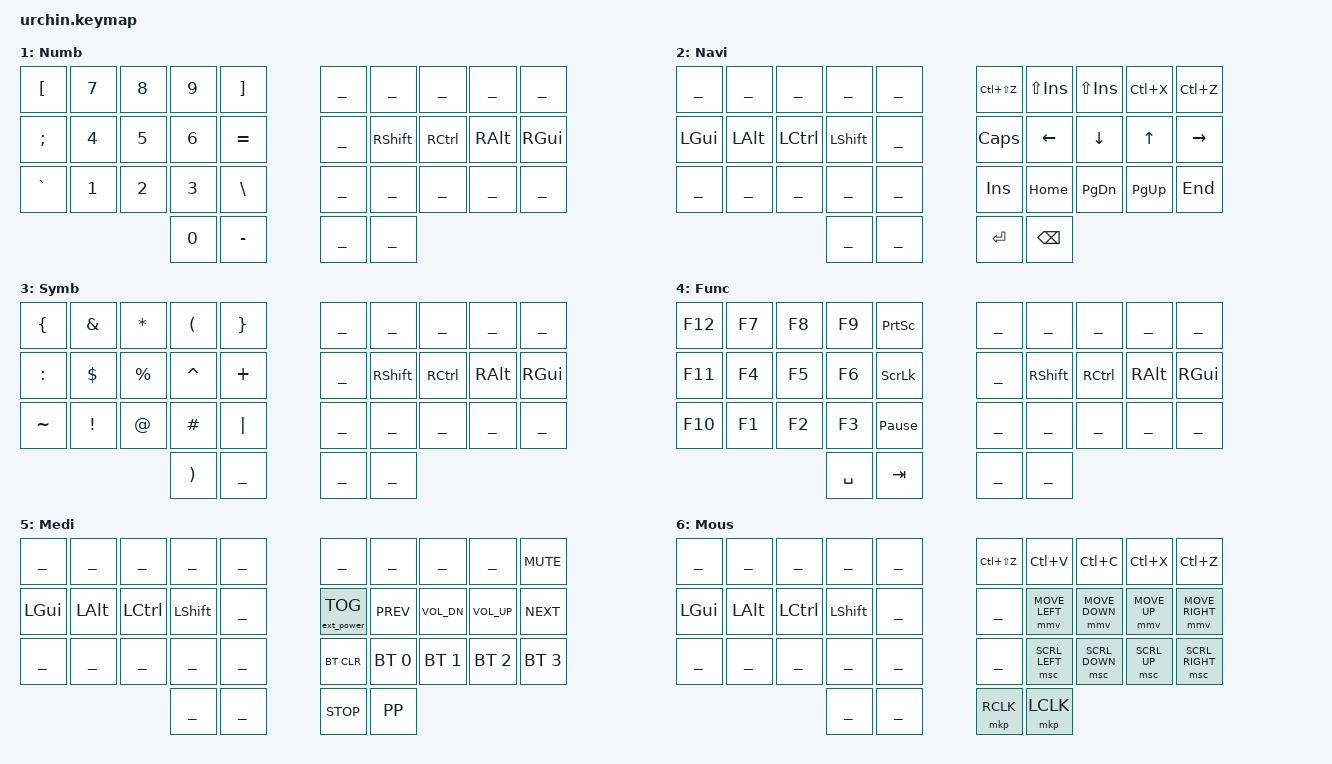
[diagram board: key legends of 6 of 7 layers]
// Copyright (c) 2022 The ZMK Contributors
// SPDX-License-Identifier: MIT

#include <behaviors.dtsi>
#include <dt-bindings/zmk/keys.h>
#include <dt-bindings/zmk/bt.h>
#include <dt-bindings/zmk/outputs.h>
#include <dt-bindings/zmk/ext_power.h>
#include <dt-bindings/zmk/pointing.h>

#include "zmk-helpers/helper.h"
#include "zmk-helpers/key-labels/34.h"

#include "constants.h"

#include "behaviors/combos.dtsi"
#include "behaviors/mod-morph.dtsi"
#include "behaviors/hold-tap.dtsi"

/ {
    keymap {
        compatible = "zmk,keymap";

        base {
            display-name = "Base";
            bindings = <
        //╭──────────┬──────────┬──────────┬──────────┬──────────╮   ╭──────────┬──────────┬──────────┬──────────┬──────────╮
        //│  Q       │  W       │  F       │  P       │  B       │   │  J       │  L       │  U       │  Y       │  ' "     │
            &kp Q      &kp W      &kp F      &kp P      &kp B          &kp J      &kp L      &kp U      &kp Y      &kp SQT
        //├──────────┼──────────┼──────────┼──────────┼──────────┤   ├──────────┼──────────┼──────────┼──────────┼──────────┤
        //│  A       │  R       │  S       │  T       │  G       │   │  M       │  N       │  E       │  I       │  O       │
            HRML(A,        R,         S,         T)     &kp G          &kp M      HRMR(N,        E,         I,        O)
        //├──────────┼──────────┼──────────┼──────────┼──────────┤   ├──────────┼──────────┼──────────┼──────────┼──────────┤
        //│  Z       │  X       │  C       │  D       │  V       │   │  K       │  H       │ , <      │ . >      │ / ?      │
            &kp Z      &kp X      &kp C      &kp D      &kp V          &kp K      &kp H      &kp COMMA  &kp DOT    &kp FSLH
        //╰──────────┴──────────┴──────────┼──────────┼──────────┤   ├──────────┼──────────┼──────────┴──────────┴──────────╯
                                            &lt NAV SPACE &lt MOU TAB  &lt SYM ENTER &bs_del_num
        //                                 ╰──────────┴──────────╯   ╰──────────┴──────────╯
            >;
        };

        // 1. NUM - number
        number {
            display-name = "Numb";
            bindings = <
        //╭──────────┬──────────┬──────────┬──────────┬──────────╮   ╭──────────┬──────────┬──────────┬──────────┬──────────╮
        //│  [       │  7       │  8       │  9       │  ]       │   │          │          │          │          │          │
            &kp LBKT   &kp N7     &kp N8     &kp N9     &kp RBKT       ___        ___        ___        ___        ___ 
        //├──────────┼──────────┼──────────┼──────────┼──────────┤   ├──────────┼──────────┼──────────┼──────────┼──────────┤
        //│  ;       │  4       │  5       │  6       │  =       │   │          │  SHIFT   │  CTRL    │  ALT     │  GUI     │
            &kp SEMI   &kp N4     &kp N5     &kp N6     &kp EQUAL      ___        &kp RSHFT  &kp RCTRL  &kp RALT   &kp RGUI
        //├──────────┼──────────┼──────────┼──────────┼──────────┤   ├──────────┼──────────┼──────────┼──────────┼──────────┤
        //│ `        │  1       │  2       │  3       │  \       │   │          │          │          │          │          │
            &kp GRAVE  &kp N1     &kp N2     &kp N3     &kp BSLH       ___        ___        ___        ___        ___ 
        //╰──────────┴──────────┴──────────┼──────────┼──────────┤   ├──────────┼──────────┼──────────┴──────────┴──────────╯
                                             &kp N0     &kp MINUS      ___        ___
        //                                 ╰──────────┴──────────╯   ╰──────────┴──────────╯
            >;
        };

        // 2. NAV - navigation
        navigation {
            display-name = "Navi";
            bindings = <
        //╭──────────┬──────────┬──────────┬──────────┬──────────╮   ╭──────────┬──────────┬──────────┬──────────┬──────────╮
        //│          │          │          │          │          │   │  REDO    │  PASTE   │  COPY    │  CUT     │  UNDO    │
            ___        ___        ___        ___        ___            &kp LC(LS(Z)) &kp LS(INS) &kp LS(INS) &kp LC(X) &kp LC(Z) 
        //├──────────┼──────────┼──────────┼──────────┼──────────┤   ├──────────┼──────────┼──────────┼──────────┼──────────┤
        //│  GUI     │  ALT     │  CTRL    │  SHIFT   │          │   │ CAPSLOCK │  LEFT A  │  DOWN A  │  UP A    │  RIGHT A │
            &kp LGUI   &kp LALT   &kp LCTRL  &kp LSHFT  ___            &kp CAPS   &kp LEFT   &kp DOWN   &kp UP     &kp RIGHT 
        //├──────────┼──────────┼──────────┼──────────┼──────────┤   ├──────────┼──────────┼──────────┼──────────┼──────────┤
        //│          │          │          │          │          │   │  INSERT  │  HOME    │  PAGE D  │  PAGE U  │  END     │
            ___        ___        ___        ___        ___            &kp INS    &kp HOME   &kp PG_DN  &kp PG_UP  &kp END
        //╰──────────┴──────────┴──────────┼──────────┼──────────┤   ├──────────┼──────────┼──────────┴──────────┴──────────╯
                                             ___        ___            &kp ENTER  &kp BSPC
        //                                 ╰──────────┴──────────╯   ╰──────────┴──────────╯
            >;
        };

        // 3. SYM - symbol
        symbol {
            display-name = "Symb";
            bindings = <
        //╭──────────┬──────────┬──────────┬──────────┬──────────╮   ╭──────────┬──────────┬──────────┬──────────┬──────────╮
        //│  {       │  &       │  *       │  (       │  }       │   │          │          │          │          │          │
            &kp LBRC   &kp AMPS   &kp ASTRK  &kp LPAR   &kp RBRC       ___        ___        ___        ___        ___
        //├──────────┼──────────┼──────────┼──────────┼──────────┤   ├──────────┼──────────┼──────────┼──────────┼──────────┤
        //│  :       │  $       │  %       │  ^       │  +       │   │          │  SHIFT   │  CTRL    │  ALT     │  GUI     │
            &kp COLON  &kp DLLR   &kp PRCNT  &kp CARET  &kp PLUS       ___        &kp RSHFT  &kp RCTRL  &kp RALT   &kp RGUI
        //├──────────┼──────────┼──────────┼──────────┼──────────┤   ├──────────┼──────────┼──────────┼──────────┼──────────┤
        //│  ~       │  !       │  @       │  #       │  |       │   │          │          │          │          │          │
            &kp TILDE  &kp EXCL   &kp AT     &kp HASH   &kp PIPE       ___        ___        ___        ___        ___
        //╰──────────┴──────────┴──────────┼──────────┼──────────┤   ├──────────┼──────────┼──────────┴──────────┴──────────╯
                                             &kp RPAR   &kp UNDER      ___        ___
        //                                 ╰──────────┴──────────╯   ╰──────────┴──────────╯
            >;
        };

        // 4. FUN - function
        function {
            display-name = "Func";
            bindings = <
        //╭──────────┬──────────┬──────────┬──────────┬──────────╮   ╭──────────┬──────────┬──────────┬──────────┬──────────╮
        //│  F12     │  F7      │  F8      │  F9      │ PRINTSCR │   │          │          │          │          │          │
            &kp F12    &kp F7     &kp F8     &kp F9     &kp PSCRN      ___        ___        ___        ___        ___ 
        //├──────────┼──────────┼──────────┼──────────┼──────────┤   ├──────────┼──────────┼──────────┼──────────┼──────────┤
        //│  F11     │  F4      │  F5      │  F6      │ SCROLLLO │   │          │  SHIFT   │  CTRL    │  ALT     │  GUI     │
            &kp F11    &kp F4     &kp F5     &kp F6     &kp SLCK       ___        &kp RSHFT  &kp RCTRL  &kp RALT   &kp RGUI
        //├──────────┼──────────┼──────────┼──────────┼──────────┤   ├──────────┼──────────┼──────────┼──────────┼──────────┤
        //│  F10     │  F1      │  F2      │  F3      │ PAUS/BRK │   │          │          │          │          │          │
            &kp F10    &kp F1     &kp F2     &kp F3     &kp PAUSE_BREAK  ___      ___        ___        ___        ___
        //╰──────────┴──────────┴──────────┼──────────┼──────────┤   ├──────────┼──────────┼──────────┴──────────┴──────────╯
                                             &kp SPACE  &kp TAB        ___        ___
        //                                 ╰──────────┴──────────╯   ╰──────────┴──────────╯
            >;
        };

        // 5. MED - media
        media {
            display-name = "Medi";
            bindings = <
        //╭──────────┬──────────┬──────────┬──────────┬──────────╮   ╭──────────┬──────────┬──────────┬──────────┬──────────╮
        //│          │          │          │          │          │   │          │          │          │          │  MUTE    │
            ___        ___        ___        ___        ___            ___        ___        ___        ___        &kp K_MUTE
        //├──────────┼──────────┼──────────┼──────────┼──────────┤   ├──────────┼──────────┼──────────┼──────────┼──────────┤
        //│  GUI     │  ALT     │  CTRL    │  SHIFT   │          │   │ EP Tog   │ PREVIOUS │ VOL DOWN │  VOL UP  │  NEXT    │
            &kp LGUI   &kp LALT   &kp LCTRL  &kp LSHFT  ___        &ext_power EP_TOG &kp K_PREV &kp K_VOL_DN &kp K_VOL_UP &kp K_NEXT
        //├──────────┼──────────┼──────────┼──────────┼──────────┤   ├──────────┼──────────┼──────────┼──────────┼──────────┤
        //│          │          │          │          │          │   │ CLEAR BT │PROFILE 0 │PROFILE 1 │PROFILE 2 │PROFILE 3 │
            ___        ___        ___        ___        ___        &bt BT_CLR &bt BT_SEL 0 &bt BT_SEL 1 &bt BT_SEL 2 &bt BT_SEL 3
        //╰──────────┴──────────┴──────────┼──────────┼──────────┤   ├──────────┼──────────┼──────────┴──────────┴──────────╯
                                             ___        ___            &kp K_STOP &kp K_PP
        //                                 ╰──────────┴──────────╯   ╰──────────┴──────────╯
            >;
        };

        // 6. MOU - mouse
        mouse {
            display-name = "Mous";
            bindings = <
        //╭──────────┬──────────┬──────────┬──────────┬──────────╮   ╭──────────┬──────────┬──────────┬──────────┬──────────╮
        //│          │          │          │          │          │   │  REDO    │  PASTE   │  COPY    │  CUT     │  UNDO    │
            ___        ___        ___        ___        ___         &kp LC(LS(Z)) &kp LC(V)  &kp LC(C)  &kp LC(X)  &kp LC(Z)
        //├──────────┼──────────┼──────────┼──────────┼──────────┤   ├──────────┼──────────┼──────────┼──────────┼──────────┤
        //│  GUI     │  ALT     │  CTRL    │  SHIFT   │          │   │          │MOVE LEFT │MOVE DOWN │MOVE UP   │MOVE RIGHT│
            &kp LGUI   &kp LALT   &kp LCTRL  &kp LSHFT  ___            ___ &mmv MOVE_LEFT &mmv MOVE_DOWN &mmv MOVE_UP &mmv MOVE_RIGHT 
        //├──────────┼──────────┼──────────┼──────────┼──────────┤   ├──────────┼──────────┼──────────┼──────────┼──────────┤
        //│          │          │          │          │          │   │          │SCRL LEFT │SCRL DOWN │SCRL UP   │SCRL RIGHT│
            ___        ___        ___        ___        ___            ___ &msc SCRL_LEFT &msc SCRL_DOWN &msc SCRL_UP &msc SCRL_RIGHT
        //╰──────────┴──────────┴──────────┼──────────┼──────────┤   ├──────────┼──────────┼──────────┴──────────┴──────────╯
                                             ___        ___            &mkp RCLK  &mkp LCLK 
        //                                 ╰──────────┴──────────╯   ╰──────────┴──────────╯
            >;
        };

    };
};
